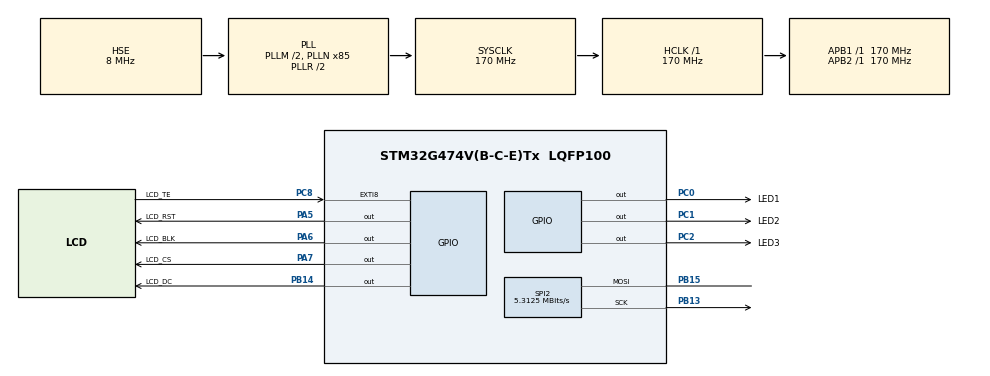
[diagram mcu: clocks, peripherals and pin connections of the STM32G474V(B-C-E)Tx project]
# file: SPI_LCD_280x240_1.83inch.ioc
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Mcu.Family=STM32G4
Mcu.Name=STM32G474V(B-C-E)Tx
Mcu.Package=LQFP100
NVIC.EXTI9_5_IRQn=true\:0\:0\:false\:false\:true\:true\:true\:true
NVIC.PriorityGroup=NVIC_PRIORITYGROUP_4
PA5.GPIO_Label=LCD_RST
PA5.Signal=GPIO_Output
PA6.GPIO_Label=LCD_BLK
PA6.Signal=GPIO_Output
PA7.GPIO_Label=LCD_CS
PA7.Signal=GPIO_Output
PB13.Mode=Simplex_Bidirectional_Master
PB13.Signal=SPI2_SCK
PB14.GPIO_Label=LCD_DC
PB14.Signal=GPIO_Output
PB15.Mode=Simplex_Bidirectional_Master
PB15.Signal=SPI2_MOSI
PC0.GPIO_Label=LED1
PC0.Signal=GPIO_Output
PC1.GPIO_Label=LED2
PC1.Signal=GPIO_Output
PC2.GPIO_Label=LED3
PC2.Signal=GPIO_Output
PC8.GPIO_Label=LCD_TE
PC8.Signal=GPXTI8
PF0-OSC_IN.Mode=HSE-External-Oscillator
PF0-OSC_IN.Signal=RCC_OSC_IN
PF1-OSC_OUT.Mode=HSE-External-Oscillator
PF1-OSC_OUT.Signal=RCC_OSC_OUT
ProjectManager.HeapSize=0x200
ProjectManager.StackSize=0x400
ProjectManager.TargetToolchain=MDK-ARM V5.32
RCC.ADC12Freq_Value=170000000
RCC.ADC345Freq_Value=170000000
RCC.AHBFreq_Value=170000000
RCC.APB1Freq_Value=170000000
RCC.APB1TimFreq_Value=170000000
RCC.APB2Freq_Value=170000000
RCC.APB2TimFreq_Value=170000000
RCC.CortexFreq_Value=170000000
RCC.EXTERNAL_CLOCK_VALUE=12288000
RCC.FLatency=FLASH_LATENCY_4
RCC.HCLKFreq_Value=170000000
RCC.HSE_VALUE=8000000
RCC.HSI48_VALUE=48000000
RCC.HSI_VALUE=16000000
RCC.LSE_VALUE=32768
RCC.PLLM=RCC_PLLM_DIV2
RCC.PLLN=85
RCC.PLLSourceVirtual=RCC_PLLSOURCE_HSE
RCC.PWR_Regulator_Voltage_Scale=PWR_REGULATOR_VOLTAGE_SCALE1_BOOST
RCC.SYSCLKFreq_VALUE=170000000
RCC.SYSCLKSource=RCC_SYSCLKSOURCE_PLLCLK
RCC.USBFreq_Value=170000000
RCC.VCOOutputFreq_Value=340000000
SPI2.BaudRatePrescaler=SPI_BAUDRATEPRESCALER_32
SPI2.CLKPhase=SPI_PHASE_2EDGE
SPI2.CLKPolarity=SPI_POLARITY_HIGH
SPI2.CalculateBaudRate=5.3125 MBits/s
SPI2.DataSize=SPI_DATASIZE_9BIT
SPI2.Direction=SPI_DIRECTION_1LINE
SPI2.Mode=SPI_MODE_MASTER
SPI2.VirtualType=VM_MASTER
VP_SYS_VS_DBSignals.Mode=DisableDeadBatterySignals
board=custom

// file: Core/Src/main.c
/* USER CODE BEGIN Header */
/**
  ******************************************************************************
  * @file           : main.c
  * @brief          : Main program body
  ******************************************************************************
  * @attention
  *
  * Copyright (c) 2024 STMicroelectronics.
  * All rights reserved.
  *
  * This software is licensed under terms that can be found in the LICENSE file
  * in the root directory of this software component.
  * If no LICENSE file comes with this software, it is provided AS-IS.
  *
  ******************************************************************************
  */
/* USER CODE END Header */
#include "main.h"
#include "spi.h"
#include "gpio.h"

/* USER CODE BEGIN Includes */
#include "lcd.h"

/* USER CODE END Includes */

void SystemClock_Config(void);

int main(void)
{

  /* MCU Configuration--------------------------------------------------------*/

  /* Reset of all peripherals, Initializes the Flash interface and the Systick. */
  HAL_Init();

  /* Configure the system clock */
  SystemClock_Config();

  /* Initialize all configured peripherals */
  MX_GPIO_Init();
  MX_SPI2_Init();
  /* USER CODE BEGIN 2 */
    Lcd_Init();
    Lcd_Fill(0, 0, LCD_W, LCD_H, MAGENTA);

    Lcd_print(90,  50,   RED, "X Pulse");
    Lcd_print(90,  80,  BLUE, "X Pulse");
    Lcd_print(90, 110, GREEN, "X Pulse");
    Lcd_print(50, 200, LIGHTBLUE, "2024-01-01 00:00:01");
    HAL_Delay(1000);
  /* USER CODE END 2 */

  /* Infinite loop */
  while (1)
  {

  }
}

void SystemClock_Config(void)
{
  RCC_OscInitTypeDef RCC_OscInitStruct = {0};
  RCC_ClkInitTypeDef RCC_ClkInitStruct = {0};

  /** Configure the main internal regulator output voltage
  */
  HAL_PWREx_ControlVoltageScaling(PWR_REGULATOR_VOLTAGE_SCALE1_BOOST);

  /** Initializes the RCC Oscillators according to the specified parameters
  * in the RCC_OscInitTypeDef structure.
  */
  RCC_OscInitStruct.OscillatorType = RCC_OSCILLATORTYPE_HSE;
  RCC_OscInitStruct.HSEState = RCC_HSE_ON;
  RCC_OscInitStruct.PLL.PLLState = RCC_PLL_ON;
  RCC_OscInitStruct.PLL.PLLSource = RCC_PLLSOURCE_HSE;
  RCC_OscInitStruct.PLL.PLLM = RCC_PLLM_DIV2;
  RCC_OscInitStruct.PLL.PLLN = 85;
  RCC_OscInitStruct.PLL.PLLP = RCC_PLLP_DIV2;
  RCC_OscInitStruct.PLL.PLLQ = RCC_PLLQ_DIV2;
  RCC_OscInitStruct.PLL.PLLR = RCC_PLLR_DIV2;
  if (HAL_RCC_OscConfig(&RCC_OscInitStruct) != HAL_OK)
  {
    Error_Handler();
  }

  /** Initializes the CPU, AHB and APB buses clocks
  */
  RCC_ClkInitStruct.ClockType = RCC_CLOCKTYPE_HCLK|RCC_CLOCKTYPE_SYSCLK
                              |RCC_CLOCKTYPE_PCLK1|RCC_CLOCKTYPE_PCLK2;
  RCC_ClkInitStruct.SYSCLKSource = RCC_SYSCLKSOURCE_PLLCLK;
  RCC_ClkInitStruct.AHBCLKDivider = RCC_SYSCLK_DIV1;
  RCC_ClkInitStruct.APB1CLKDivider = RCC_HCLK_DIV1;
  RCC_ClkInitStruct.APB2CLKDivider = RCC_HCLK_DIV1;

  if (HAL_RCC_ClockConfig(&RCC_ClkInitStruct, FLASH_LATENCY_4) != HAL_OK)
  {
    Error_Handler();
  }
}

void Error_Handler(void)
{
  __disable_irq();
  while (1)
  {
  }
}
